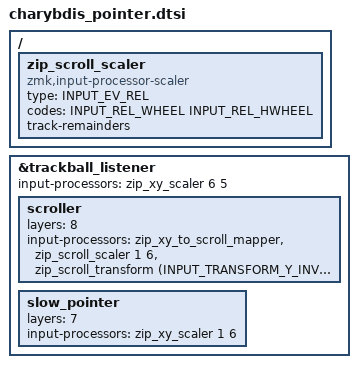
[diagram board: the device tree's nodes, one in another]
#include <dt-bindings/zmk/pointing.h>
#include <input/processors.dtsi>
#include <dt-bindings/zmk/input_transform.h>
#include <zephyr/dt-bindings/input/input-event-codes.h>
// #include "features/mouse.dtsi"

/ {
  zip_scroll_scaler: zip_scroll_scaler {
    compatible = "zmk,input-processor-scaler";
    #input-processor-cells = <2>;
    type = <INPUT_EV_REL>;
    codes = <INPUT_REL_WHEEL INPUT_REL_HWHEEL>;
    track-remainders;
  };
};

&trackball_listener {
    /* base processor chain on all layers */
    input-processors = <&zip_xy_scaler 6 5>;

    /* layer-8 scroll override */
    scroller: scroller {
        layers           = <8>;
        input-processors = <
            &zip_xy_to_scroll_mapper                         // Converts XY movement to scroll events
            &zip_scroll_scaler 1 6                           // Scales the scroll speed (e.g., 1/6 speed)
            &zip_scroll_transform (INPUT_TRANSFORM_Y_INVERT) // Inverts the scroll direction
        >;
    };

    /* layer-7 slow-pointer override */
    slow_pointer: slow_pointer {
        layers           = <7>;
        input-processors = <&zip_xy_scaler 1 6>;
    };
};
